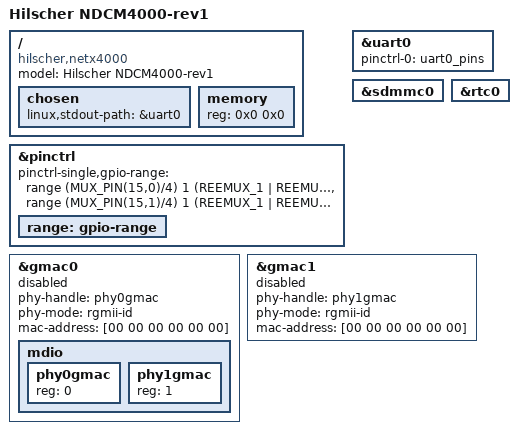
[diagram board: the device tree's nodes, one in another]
/*
* Device tree for Hilscher netX4000 based NDCM4000 rev1 modules
*
* arch/arm/boot/dts/netx4000/ndcm4000-rev1.dtsi
*
* (C) Copyright 2015 Hilscher Gesellschaft fuer Systemautomation mbH
* http://www.hilscher.com
*
* This program is free software; you can redistribute it and/or
* modify it under the terms of the GNU General Public License as
* published by the Free Software Foundation; version 2 of
* the License.
*
* This program is distributed in the hope that it will be useful,
* but WITHOUT ANY WARRANTY; without even the implied warranty of
* MERCHANTABILITY or FITNESS FOR A PARTICULAR PURPOSE.  See the
* GNU General Public License for more details.
*
*/

/dts-v1/;

#include "netx4000-common.dtsi"

/ {
	model = "Hilscher NDCM4000-rev1";
	compatible = "hilscher,netx4000";

	chosen {
		linux,stdout-path = &uart0;
	};

	memory {
		device_type = "memory";
		reg = <0x0 0x0>; /* will be filled by bootloader */
	};
};

/* Static platform gpio pins */
&pinctrl {
	pinctrl-single,gpio-range = <
		&range (MUX_PIN(15,0)/4) 1 (REEMUX_1 | REEMUX_DRV_04MA | REEMUX_UDC_PULLUP50K | REEMUX_CTL(0x8)) // gpio4[0] / mdio (gpio-bitbang)
		&range (MUX_PIN(15,1)/4) 1 (REEMUX_1 | REEMUX_DRV_04MA | REEMUX_UDC_NONE | REEMUX_CTL(0x8))      // gpio4[1] / mdc (gpio-bitbang)
	>;

	range: gpio-range {
		#pinctrl-single,gpio-range-cells = <3>;
	};
};

&uart0 {
	status = "ok";
	pinctrl-names = "default";
	pinctrl-0 = <&uart0_pins>;
};

&sdmmc0 {
	status = "ok";
};

&rtc0 {
	status = "ok";
};

&gmac0 {
	status = "disabled";
	phy-handle = <&phy0gmac>;
	phy-mode = "rgmii-id";
	mac-address = [00 00 00 00 00 00]; /* will be filled by bootloader */

	mdio {
		#address-cells = <1>;
		#size-cells = <0>;
		phy0gmac: phy0gmac {
			reg = <0>;
		};
		phy1gmac: phy1gmac {
			reg = <1>;
		};
	};
};

&gmac1 {
	status = "disabled";
	phy-handle = <&phy1gmac>;
	phy-mode = "rgmii-id";
	mac-address = [00 00 00 00 00 00]; /* will be filled by bootloader */
};
